# STM32F105VCT7 register map
File version: 1.0
Registers are 32-bit, access not given, reset 0x0 unless marked. A register's access mark holds for its fields unless they carry their own. Offsets are from the block's base; [hi:lo] are bit positions; {n}, {i} and the like mark numbered series; 'fields as' and 'values as' point back to an identical list.

## EXTI
Base 0x40010400
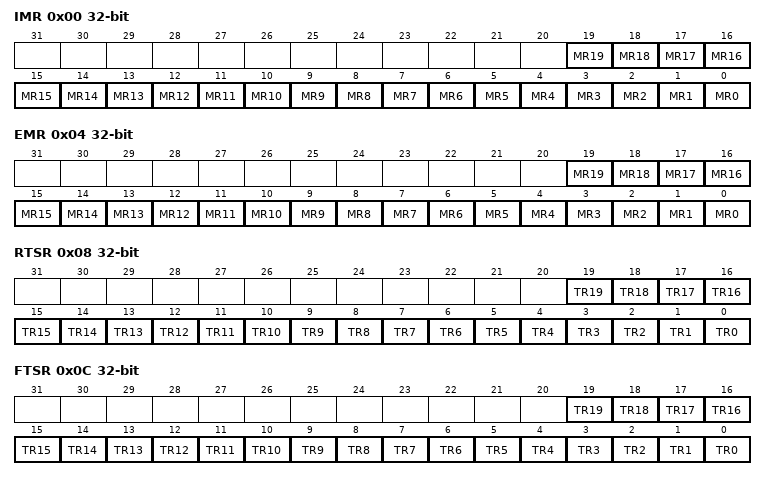
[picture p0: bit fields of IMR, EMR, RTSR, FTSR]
0x00 IMR
  [n] MR{n} (n=0..19)
0x04 EMR
  [n] MR{n} (n=0..19)
0x08 RTSR
  [n] TR{n} (n=0..19)
0x0C FTSR
  [n] TR{n} (n=0..19)
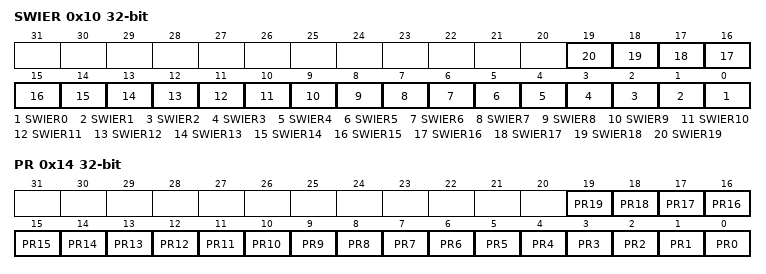
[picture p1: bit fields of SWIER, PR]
0x10 SWIER
  [n] SWIER{n} (n=0..19)
0x14 PR
  [n] PR{n} (n=0..19)

## GPIOA
Base 0x40010800
Same registers: GPIOB 0x40010C00, GPIOC 0x40011000, GPIOD 0x40011400, GPIOE 0x40011800
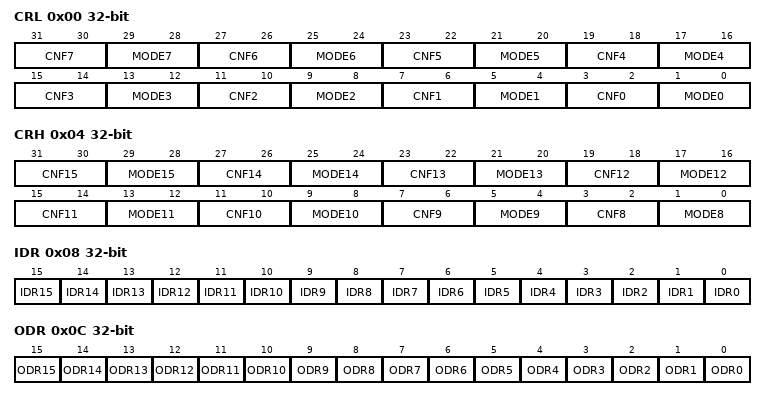
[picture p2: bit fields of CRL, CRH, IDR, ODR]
0x00 CRL
  [4n+3:4n+2] CNF{n} (n=0..7), [4n+1:4n] MODE{n} (n=0..7)
0x04 CRH
  [4n-29:4n-30] CNF{n} (n=8..15), [4n-31:4n-32] MODE{n} (n=8..15)
0x08 IDR
  [n] IDR{n} (n=0..15)
0x0C ODR
  [n] ODR{n} (n=0..15)
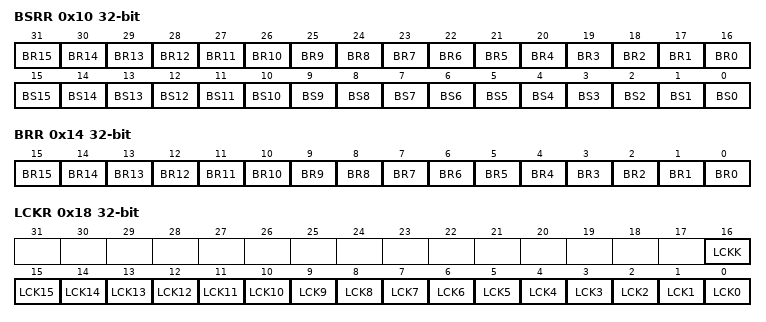
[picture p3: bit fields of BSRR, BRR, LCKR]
0x10 BSRR
  [n+16] BR{n} (n=0..15), [n] BS{n} (n=0..15)
0x14 BRR
  [n] BR{n} (n=0..15)
0x18 LCKR
  [16] LCKK, [n] LCK{n} (n=0..15)

## ADC1
Base 0x40012400
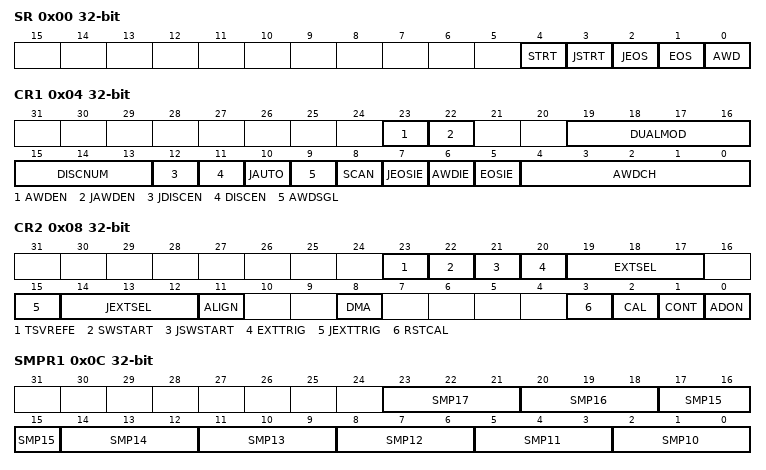
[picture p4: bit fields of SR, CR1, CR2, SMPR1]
0x00 SR
  [4] STRT, [3] JSTRT, [2] JEOS, [1] EOS, [0] AWD
0x04 CR1
  [23] AWDEN, [22] JAWDEN, [19:16] DUALMOD, [15:13] DISCNUM, [12] JDISCEN, [11] DISCEN, [10] JAUTO, [9] AWDSGL, [8] SCAN, [7] JEOSIE, [6] AWDIE, [5] EOSIE, [4:0] AWDCH
0x08 CR2
  [23] TSVREFE, [22] SWSTART, [21] JSWSTART, [20] EXTTRIG, [19:17] EXTSEL, [15] JEXTTRIG, [14:12] JEXTSEL, [11] ALIGN, [8] DMA, [3] RSTCAL, [2] CAL, [1] CONT, [0] ADON
0x0C SMPR1
  [3n-28:3n-30] SMP{n} (n=10..17)
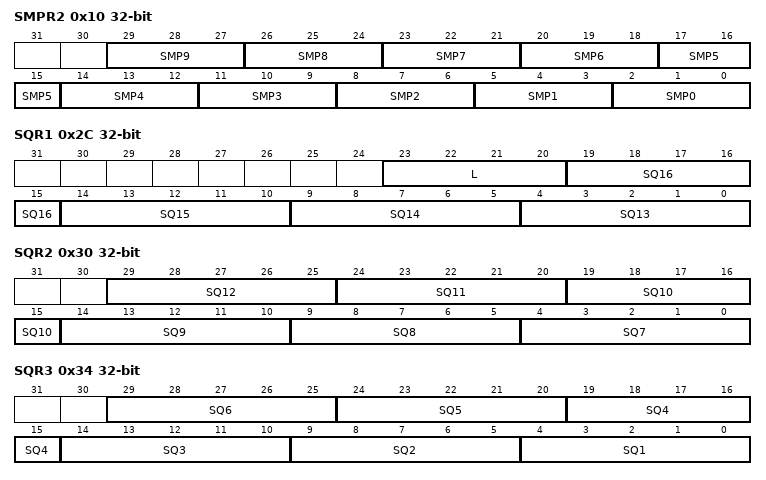
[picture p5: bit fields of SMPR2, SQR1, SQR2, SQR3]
0x10 SMPR2
  [3n+2:3n] SMP{n} (n=0..9)
{0x10+4i} JOFR{i} (i=1..4)
  [11:0] JOFFSET{i}
0x24 HTR
  [11:0] HT
0x28 LTR
  [11:0] LT
0x2C SQR1
  [23:20] L, [5n-61:5n-65] SQ{n} (n=13..16)
0x30 SQR2
  [5n-31:5n-35] SQ{n} (n=7..12)
0x34 SQR3
  [5n-1:5n-5] SQ{n} (n=1..6)
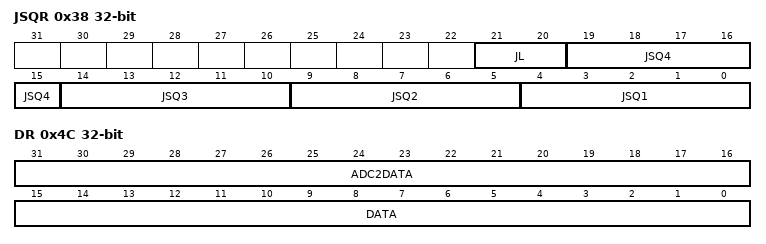
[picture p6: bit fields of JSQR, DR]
0x38 JSQR
  [21:20] JL, [5n-1:5n-5] JSQ{n} (n=1..4)
{0x38+4i} JDR{i} (i=1..4)
  [15:0] JDATA
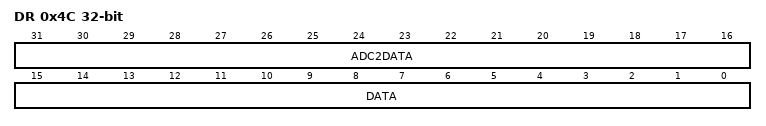
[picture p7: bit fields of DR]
0x4C DR
  [31:16] ADC2DATA, [15:0] DATA

## ADC12_COMMON
Base 0x40012400
Registers as ADC1, without SMPR1, SMPR2, JOFR{n} (n=1..4), HTR, LTR, SQR{n} (n=1..3), JSQR, JDR{n} (n=1..4).

## ADC2
Base 0x40012800
Registers as ADC1; these are added or differ:
0x4C DR
  [31:16] ADC2DATA, [15:0] DATA

## DMA1
Base 0x40020000
Same registers: DMA2 0x40020400
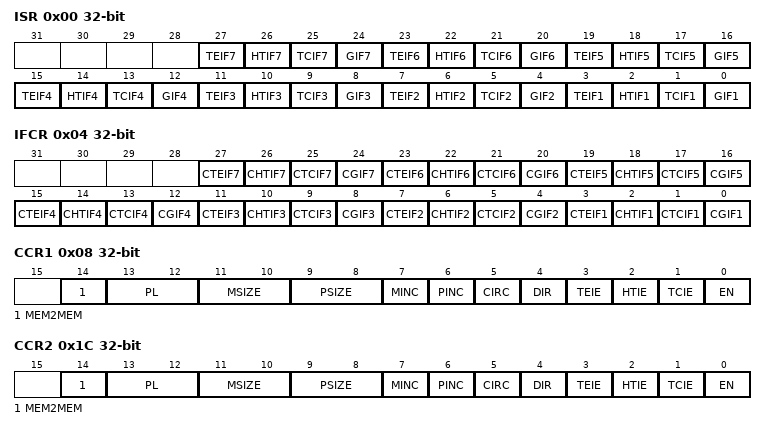
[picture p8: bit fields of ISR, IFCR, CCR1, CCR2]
0x00 ISR
  [4n-1] TEIF{n} (n=1..7), [4n-2] HTIF{n} (n=1..7), [4n-3] TCIF{n} (n=1..7), [4n-4] GIF{n} (n=1..7)
0x04 IFCR
  [4n-1] CTEIF{n} (n=1..7), [4n-2] CHTIF{n} (n=1..7), [4n-3] CTCIF{n} (n=1..7), [4n-4] CGIF{n} (n=1..7)
0x08 CCR1
  [14] MEM2MEM, [13:12] PL, [11:10] MSIZE, [9:8] PSIZE, [7] MINC, [6] PINC, [5] CIRC, [4] DIR, [3] TEIE, [2] HTIE, [1] TCIE, [0] EN
0x0C CNDTR1
  [15:0] NDT
0x10 CPAR1
  [31:0] PA
{0x0+0x14*i} CMAR{i} (i=1..7)
  [31:0] MA
0x1C CCR2
  fields as CCR1
0x20 CNDTR2
  [15:0] NDT
0x24 CPAR2
  [31:0] PA
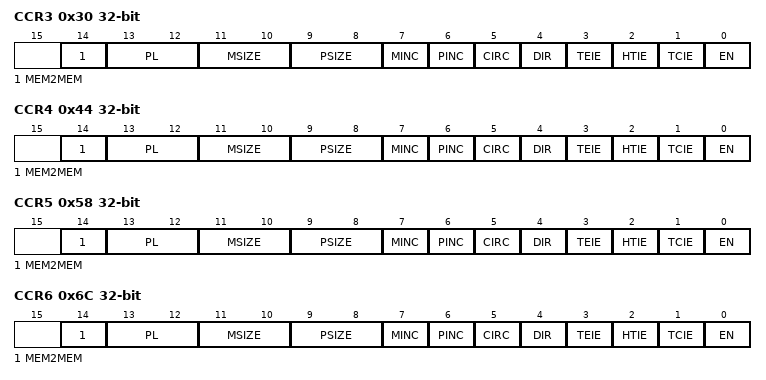
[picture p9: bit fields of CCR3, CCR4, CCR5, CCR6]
0x30 CCR3
  fields as CCR1
0x34 CNDTR3
  [15:0] NDT
0x38 CPAR3
  [31:0] PA
0x44 CCR4
  fields as CCR1
0x48 CNDTR4
  [15:0] NDT
0x4C CPAR4
  [31:0] PA
0x58 CCR5
  fields as CCR1
0x5C CNDTR5
  [15:0] NDT
0x60 CPAR5
  [31:0] PA
0x6C CCR6
  fields as CCR1
0x70 CNDTR6
  [15:0] NDT
0x74 CPAR6
  [31:0] PA
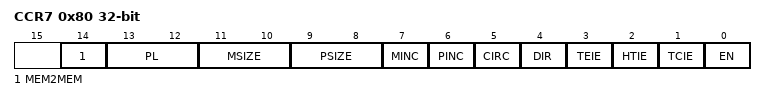
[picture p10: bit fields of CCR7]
0x80 CCR7
  fields as CCR1
0x84 CNDTR7
  [15:0] NDT
0x88 CPAR7
  [31:0] PA

## RCC
Base 0x40021000
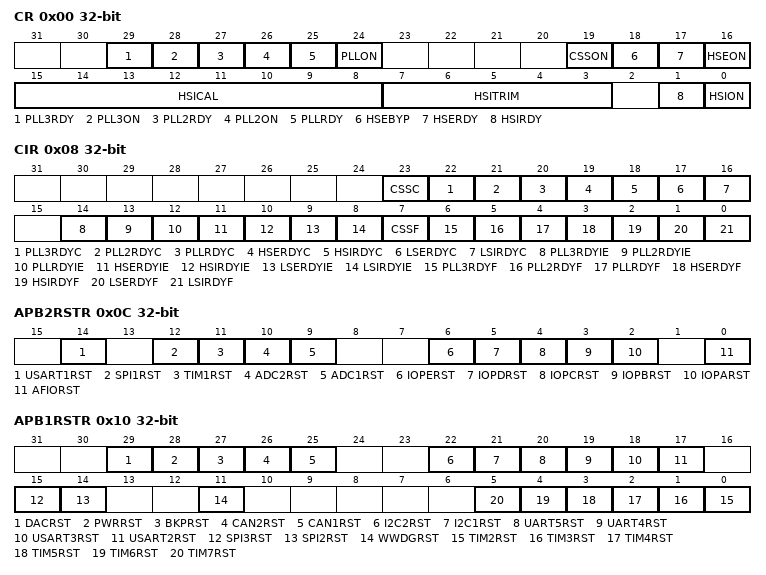
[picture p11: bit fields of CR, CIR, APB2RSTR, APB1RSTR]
0x00 CR
  [29] PLL3RDY, [28] PLL3ON, [27] PLL2RDY, [26] PLL2ON, [25] PLLRDY, [24] PLLON, [19] CSSON, [18] HSEBYP, [17] HSERDY, [16] HSEON, [15:8] HSICAL, [7:3] HSITRIM, [1] HSIRDY, [0] HSION
0x04 CFGR
  [27:24] MCO, [22] OTGFSPRE, [20] PLLMULL6, [20:19] PLLMULL8, [20:18] PLLMULL9, [17] PLLXTPRE, [16] PLLSRC, [15:14] ADCPRE, [13:11] PPRE2, [10:8] PPRE1, [7:4] HPRE, [3:2] SWS, [1:0] SW
0x08 CIR
  [23] CSSC, [22] PLL3RDYC, [21] PLL2RDYC, [20] PLLRDYC, [19] HSERDYC, [18] HSIRDYC, [17] LSERDYC, [16] LSIRDYC, [14] PLL3RDYIE, [13] PLL2RDYIE, [12] PLLRDYIE, [11] HSERDYIE, [10] HSIRDYIE, [9] LSERDYIE, [8] LSIRDYIE, [7] CSSF, [6] PLL3RDYF, [5] PLL2RDYF, [4] PLLRDYF, [3] HSERDYF, [2] HSIRDYF, [1] LSERDYF, [0] LSIRDYF
0x0C APB2RSTR
  [14] USART1RST, [12] SPI1RST, [11] TIM1RST, [10] ADC2RST, [9] ADC1RST, [6] IOPERST, [5] IOPDRST, [4] IOPCRST, [3] IOPBRST, [2] IOPARST, [0] AFIORST
0x10 APB1RSTR
  [29] DACRST, [28] PWRRST, [27] BKPRST, [26] CAN2RST, [25] CAN1RST, [22] I2C2RST, [21] I2C1RST, [20] UART5RST, [19] UART4RST, [18] USART3RST, [17] USART2RST, [15] SPI3RST, [14] SPI2RST, [11] WWDGRST, [n-2] TIM{n}RST (n=2..7)
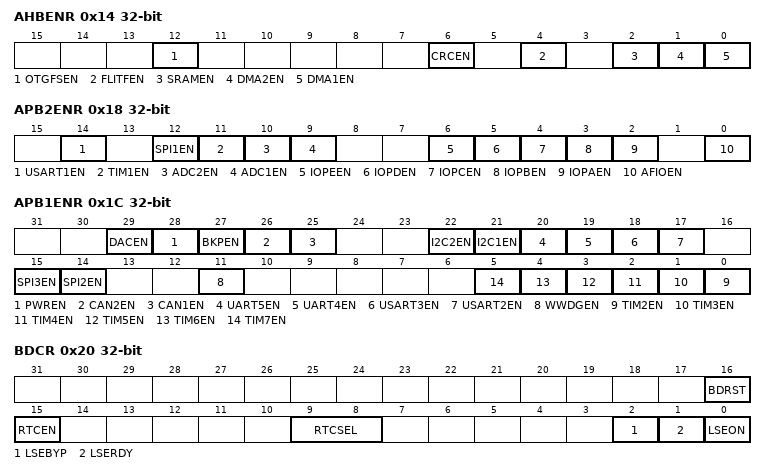
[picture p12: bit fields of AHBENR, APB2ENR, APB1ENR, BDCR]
0x14 AHBENR
  [12] OTGFSEN, [6] CRCEN, [4] FLITFEN, [2] SRAMEN, [1] DMA2EN, [0] DMA1EN
0x18 APB2ENR
  [14] USART1EN, [12] SPI1EN, [11] TIM1EN, [10] ADC2EN, [9] ADC1EN, [6] IOPEEN, [5] IOPDEN, [4] IOPCEN, [3] IOPBEN, [2] IOPAEN, [0] AFIOEN
0x1C APB1ENR
  [29] DACEN, [28] PWREN, [27] BKPEN, [26] CAN2EN, [25] CAN1EN, [22] I2C2EN, [21] I2C1EN, [20] UART5EN, [19] UART4EN, [18] USART3EN, [17] USART2EN, [15] SPI3EN, [14] SPI2EN, [11] WWDGEN, [n-2] TIM{n}EN (n=2..7)
0x20 BDCR
  [16] BDRST, [15] RTCEN, [9:8] RTCSEL, [2] LSEBYP, [1] LSERDY, [0] LSEON
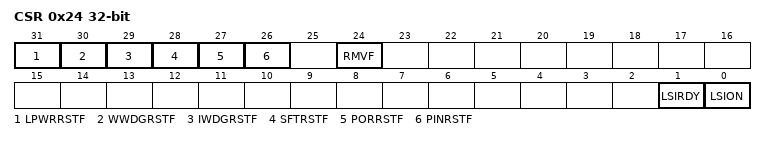
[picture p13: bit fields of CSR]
0x24 CSR
  [31] LPWRRSTF, [30] WWDGRSTF, [29] IWDGRSTF, [28] SFTRSTF, [27] PORRSTF, [26] PINRSTF, [24] RMVF, [1] LSIRDY, [0] LSION
0x28 AHBRSTR
  [12] OTGFSRST
0x2C CFGR2
  [18] I2S3SRC, [17] I2S2SRC, [16] PREDIV1SRC_PLL2, [15] PLL3MUL10, [15:14] PLL3MUL14, [14:13] PLL3MUL8, [14:12] PLL3MUL9, [11] PLL2MUL10, [11:10] PLL2MUL14, [10:9] PLL2MUL8, [10:8] PLL2MUL9, [7] PREDIV2_DIV9, [6] PREDIV2_DIV5, [6:5] PREDIV2_DIV7, [6:4] PREDIV2_DIV8, [3] PREDIV1_DIV9, [2] PREDIV1_DIV5, [2:1] PREDIV1_DIV7, [2:0] PREDIV1_DIV8

## FLASH
Base 0x40022000
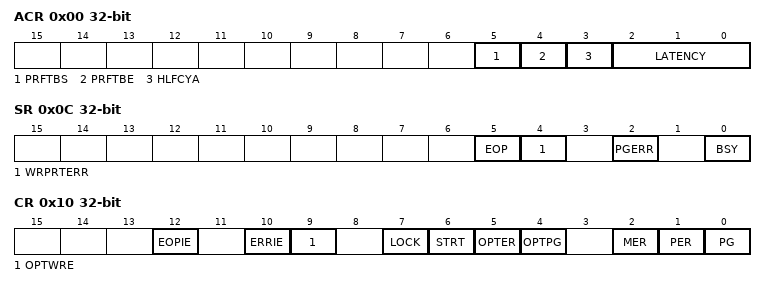
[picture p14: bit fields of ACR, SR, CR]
0x00 ACR
  [5] PRFTBS, [4] PRFTBE, [3] HLFCYA, [2:0] LATENCY
0x04 KEYR
  [31:0] FKEYR
0x08 OPTKEYR
0x0C SR
  [5] EOP, [4] WRPRTERR, [2] PGERR, [0] BSY
0x10 CR
  [12] EOPIE, [10] ERRIE, [9] OPTWRE, [7] LOCK, [6] STRT, [5] OPTER, [4] OPTPG, [2] MER, [1] PER, [0] PG
0x14 AR
  [31:0] FAR
0x1C OBR
  [25:18] DATA1, [17:10] DATA0, [4] nRST_STDBY, [3] nRST_STOP, [4:2] USER, [1] RDPRT, [0] OPTERR
0x20 WRPR
  [31:0] WRP

## CRC
Base 0x40023000
0x00 DR
0x04 IDR 8-bit
0x08 CR
  [0] RESET

## USB_OTG_FS
Base 0x50000000
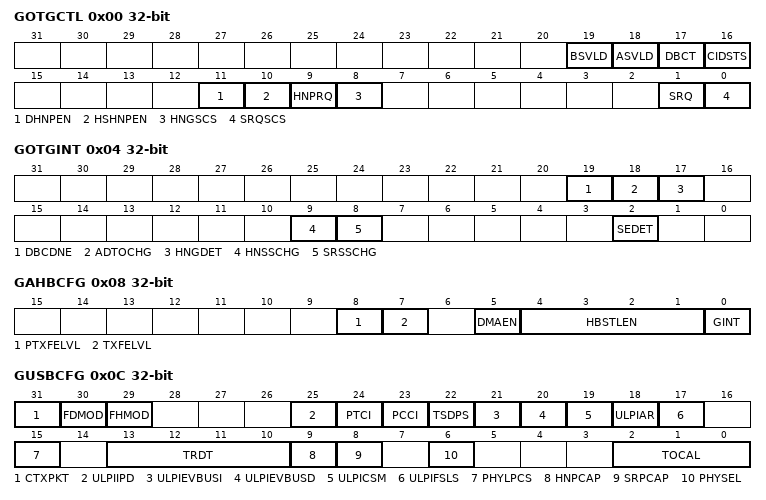
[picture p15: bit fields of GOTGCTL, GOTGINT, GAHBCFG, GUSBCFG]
0x00 GOTGCTL
  [19] BSVLD, [18] ASVLD, [17] DBCT, [16] CIDSTS, [11] DHNPEN, [10] HSHNPEN, [9] HNPRQ, [8] HNGSCS, [1] SRQ, [0] SRQSCS
0x04 GOTGINT
  [19] DBCDNE, [18] ADTOCHG, [17] HNGDET, [9] HNSSCHG, [8] SRSSCHG, [2] SEDET
0x08 GAHBCFG
  [8] PTXFELVL, [7] TXFELVL, [5] DMAEN, [4:1] HBSTLEN, [0] GINT
0x0C GUSBCFG
  [31] CTXPKT, [30] FDMOD, [29] FHMOD, [25] ULPIIPD, [24] PTCI, [23] PCCI, [22] TSDPS, [21] ULPIEVBUSI, [20] ULPIEVBUSD, [19] ULPICSM, [18] ULPIAR, [17] ULPIFSLS, [15] PHYLPCS, [13:10] TRDT, [9] HNPCAP, [8] SRPCAP, [6] PHYSEL, [2:0] TOCAL
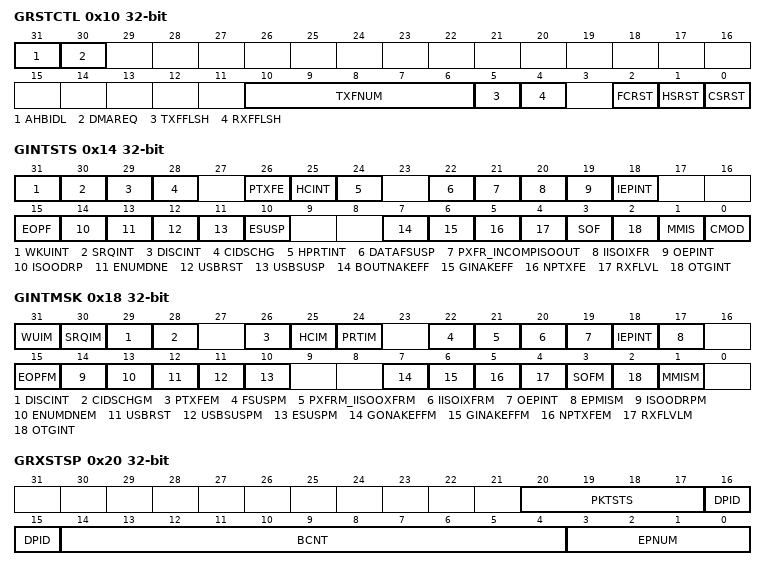
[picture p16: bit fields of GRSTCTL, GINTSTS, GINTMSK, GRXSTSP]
0x10 GRSTCTL
  [31] AHBIDL, [30] DMAREQ, [10:6] TXFNUM, [5] TXFFLSH, [4] RXFFLSH, [2] FCRST, [1] HSRST, [0] CSRST
0x14 GINTSTS
  [31] WKUINT, [30] SRQINT, [29] DISCINT, [28] CIDSCHG, [26] PTXFE, [25] HCINT, [24] HPRTINT, [22] DATAFSUSP, [21] PXFR_INCOMPISOOUT, [20] IISOIXFR, [19] OEPINT, [18] IEPINT, [15] EOPF, [14] ISOODRP, [13] ENUMDNE, [12] USBRST, [11] USBSUSP, [10] ESUSP, [7] BOUTNAKEFF, [6] GINAKEFF, [5] NPTXFE, [4] RXFLVL, [3] SOF, [2] OTGINT, [1] MMIS, [0] CMOD
0x18 GINTMSK
  [31] WUIM, [30] SRQIM, [29] DISCINT, [28] CIDSCHGM, [26] PTXFEM, [25] HCIM, [24] PRTIM, [22] FSUSPM, [21] PXFRM_IISOOXFRM, [20] IISOIXFRM, [19] OEPINT, [18] IEPINT, [17] EPMISM, [15] EOPFM, [14] ISOODRPM, [13] ENUMDNEM, [12] USBRST, [11] USBSUSPM, [10] ESUSPM, [7] GONAKEFFM, [6] GINAKEFFM, [5] NPTXFEM, [4] RXFLVLM, [3] SOFM, [2] OTGINT, [1] MMISM
0x1C GRXSTSR
0x20 GRXSTSP
  [20:17] PKTSTS, [16:15] DPID, [14:4] BCNT, [3:0] EPNUM
0x24 GRXFSIZ
  [15:0] RXFD
0x28 DIEPTXF0_HNPTXFSIZ
0x2C HNPTXSTS
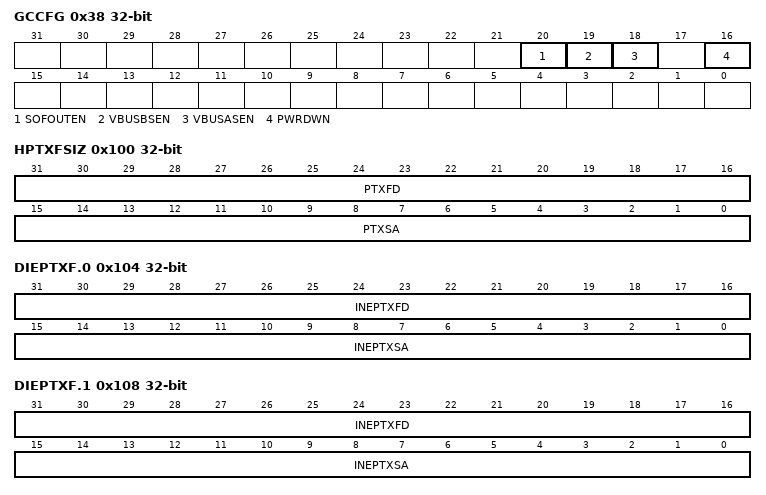
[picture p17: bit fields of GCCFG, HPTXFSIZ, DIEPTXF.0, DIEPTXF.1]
0x38 GCCFG
  [20] SOFOUTEN, [19] VBUSBSEN, [18] VBUSASEN, [16] PWRDWN
0x3C CID
  [31:0] PRODUCT_ID
0x100 HPTXFSIZ
  [31:16] PTXFD, [15:0] PTXSA
0x104 DIEPTXF.0
  [31:16] INEPTXFD, [15:0] INEPTXSA
0x108 DIEPTXF.1
  [31:16] INEPTXFD, [15:0] INEPTXSA
0x10C DIEPTXF.2
  [31:16] INEPTXFD, [15:0] INEPTXSA
0x110 DIEPTXF.3
  [31:16] INEPTXFD, [15:0] INEPTXSA
0x114 DIEPTXF.4
  [31:16] INEPTXFD, [15:0] INEPTXSA
0x118 DIEPTXF.5
  [31:16] INEPTXFD, [15:0] INEPTXSA
0x11C DIEPTXF.6
  [31:16] INEPTXFD, [15:0] INEPTXSA
0x120 DIEPTXF.7
  [31:16] INEPTXFD, [15:0] INEPTXSA
0x124 DIEPTXF.8
  [31:16] INEPTXFD, [15:0] INEPTXSA
0x128 DIEPTXF.9
  [31:16] INEPTXFD, [15:0] INEPTXSA
0x12C DIEPTXF.10
  [31:16] INEPTXFD, [15:0] INEPTXSA
0x130 DIEPTXF.11
  [31:16] INEPTXFD, [15:0] INEPTXSA
0x134 DIEPTXF.12
  [31:16] INEPTXFD, [15:0] INEPTXSA
0x138 DIEPTXF.13
  [31:16] INEPTXFD, [15:0] INEPTXSA
0x13C DIEPTXF.14
  [31:16] INEPTXFD, [15:0] INEPTXSA

## DBGMCU
Base 0xE0042000
0x00 IDCODE
  [31:16] REV_ID, [11:0] DEV_ID
0x04 CR
  [30] DBG_TIM11_STOP, [29] DBG_TIM10_STOP, [28] DBG_TIM9_STOP, [21] DBG_CAN2_STOP, [20] DBG_TIM7_STOP, [19] DBG_TIM6_STOP, [18] DBG_TIM5_STOP, [16] DBG_I2C2_SMBUS_TIMEOUT, [15] DBG_I2C1_SMBUS_TIMEOUT, [14] DBG_CAN1_STOP, [n+9] DBG_TIM{n}_STOP (n=1..4), [9] DBG_WWDG_STOP, [8] DBG_IWDG_STOP, [7:6] TRACE_MODE, [5] TRACE_IOEN, [2] DBG_STANDBY, [1] DBG_STOP, [0] DBG_SLEEP
